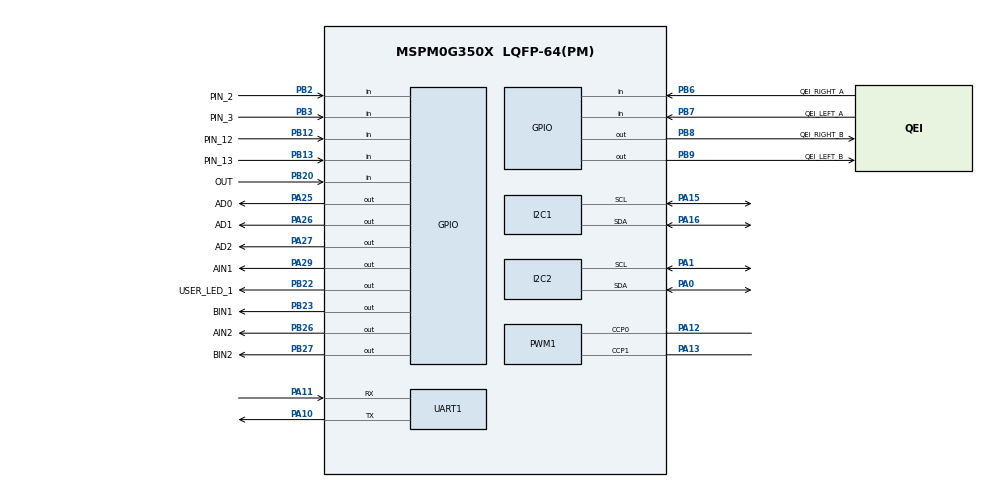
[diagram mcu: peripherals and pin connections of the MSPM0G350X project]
/**
 * @cliArgs --device "MSPM0G350X" --part "Default" --package "LQFP-64(PM)" --product "mspm0_sdk@2.10.00.04"
 * @versions {"tool":"1.26.2+4477"}
 */

/**
 * Import the modules used in this configuration.
 */
const GPIO   = scripting.addModule("/ti/driverlib/GPIO", {}, false);
const GPIO1  = GPIO.addInstance();
const GPIO2  = GPIO.addInstance();
const GPIO3  = GPIO.addInstance();
const GPIO4  = GPIO.addInstance();
const GPIO5  = GPIO.addInstance();
const I2C    = scripting.addModule("/ti/driverlib/I2C", {}, false);
const I2C1   = I2C.addInstance();
const I2C2   = I2C.addInstance();
const PWM    = scripting.addModule("/ti/driverlib/PWM", {}, false);
const PWM1   = PWM.addInstance();
const SYSCTL = scripting.addModule("/ti/driverlib/SYSCTL");
const TIMER  = scripting.addModule("/ti/driverlib/TIMER", {}, false);
const TIMER1 = TIMER.addInstance();
const UART   = scripting.addModule("/ti/driverlib/UART", {}, false);
const UART1  = UART.addInstance();

/**
 * Write custom configuration values to the imported modules.
 */
GPIO1.$name                         = "GPIO_LEDS";
GPIO1.associatedPins[0].$name       = "USER_LED_1";
GPIO1.associatedPins[0].pin.$assign = "PB22";

const Board = scripting.addModule("/ti/driverlib/Board", {}, false);

GPIO2.$name                         = "GPIO_MOTOR";
GPIO2.associatedPins.create(4);
GPIO2.associatedPins[0].$name       = "AIN1";
GPIO2.associatedPins[0].pin.$assign = "PA29";
GPIO2.associatedPins[1].$name       = "AIN2";
GPIO2.associatedPins[1].pin.$assign = "PB26";
GPIO2.associatedPins[2].$name       = "BIN1";
GPIO2.associatedPins[2].pin.$assign = "PB23";
GPIO2.associatedPins[3].$name       = "BIN2";
GPIO2.associatedPins[3].pin.$assign = "PB27";

GPIO3.$name                         = "GPIO_SENSOR";
GPIO3.associatedPins.create(4);
GPIO3.associatedPins[0].$name       = "AD0";
GPIO3.associatedPins[0].pin.$assign = "PA25";
GPIO3.associatedPins[1].$name       = "AD1";
GPIO3.associatedPins[1].pin.$assign = "PA26";
GPIO3.associatedPins[2].$name       = "AD2";
GPIO3.associatedPins[2].pin.$assign = "PA27";
GPIO3.associatedPins[3].$name       = "OUT";
GPIO3.associatedPins[3].direction   = "INPUT";
GPIO3.associatedPins[3].pin.$assign = "PB20";

GPIO4.$name                         = "GPIO_ENCODER";
GPIO4.associatedPins.create(4);
GPIO4.associatedPins[0].$name       = "QEI_LEFT_A";
GPIO4.associatedPins[0].direction   = "INPUT";
GPIO4.associatedPins[0].pin.$assign = "PB7";
GPIO4.associatedPins[1].$name       = "QEI_RIGHT_A";
GPIO4.associatedPins[1].direction   = "INPUT";
GPIO4.associatedPins[1].pin.$assign = "PB6";
GPIO4.associatedPins[2].$name       = "QEI_LEFT_B";
GPIO4.associatedPins[2].pin.$assign = "PB9";
GPIO4.associatedPins[3].$name       = "QEI_RIGHT_B";
GPIO4.associatedPins[3].pin.$assign = "PB8";

GPIO5.$name                              = "GPIO_KEYS";
GPIO5.associatedPins.create(4);
GPIO5.associatedPins[0].$name            = "PIN_2";
GPIO5.associatedPins[0].direction        = "INPUT";
GPIO5.associatedPins[0].internalResistor = "PULL_UP";
GPIO5.associatedPins[0].pin.$assign      = "PB2";
GPIO5.associatedPins[1].$name            = "PIN_3";
GPIO5.associatedPins[1].direction        = "INPUT";
GPIO5.associatedPins[1].internalResistor = "PULL_UP";
GPIO5.associatedPins[1].pin.$assign      = "PB3";
GPIO5.associatedPins[2].$name            = "PIN_12";
GPIO5.associatedPins[2].direction        = "INPUT";
GPIO5.associatedPins[2].internalResistor = "PULL_UP";
GPIO5.associatedPins[2].pin.$assign      = "PB12";
GPIO5.associatedPins[3].$name            = "PIN_13";
GPIO5.associatedPins[3].direction        = "INPUT";
GPIO5.associatedPins[3].internalResistor = "PULL_UP";
GPIO5.associatedPins[3].pin.$assign      = "PB13";

I2C1.$name                     = "I2C_0";
I2C1.peripheral.sdaPin.$assign = "PA16";
I2C1.peripheral.sclPin.$assign = "PA15";
I2C1.sdaPinConfig.$name        = "ti_driverlib_gpio_GPIOPinGeneric0";
I2C1.sclPinConfig.$name        = "ti_driverlib_gpio_GPIOPinGeneric1";

I2C2.$name                     = "I2C_1";
I2C2.peripheral.sdaPin.$assign = "PA0";
I2C2.peripheral.sclPin.$assign = "PA1";
I2C2.sdaPinConfig.$name        = "ti_driverlib_gpio_GPIOPinGeneric6";
I2C2.sclPinConfig.$name        = "ti_driverlib_gpio_GPIOPinGeneric7";

PWM1.$name                              = "PWM_MOTOR";
PWM1.pwmMode                            = "EDGE_ALIGN_UP";
PWM1.timerCount                         = 2000;
PWM1.peripheral.$assign                 = "TIMG0";
PWM1.peripheral.ccp0Pin.$assign         = "PA12";
PWM1.peripheral.ccp1Pin.$assign         = "PA13";
PWM1.PWM_CHANNEL_0.$name                = "ti_driverlib_pwm_PWMTimerCC0";
PWM1.PWM_CHANNEL_1.$name                = "ti_driverlib_pwm_PWMTimerCC1";
PWM1.ccp0PinConfig.$name                = "ti_driverlib_gpio_GPIOPinGeneric2";
PWM1.ccp0PinConfig.direction            = scripting.forceWrite("OUTPUT");
PWM1.ccp0PinConfig.hideOutputInversion  = scripting.forceWrite(false);
PWM1.ccp0PinConfig.onlyInternalResistor = scripting.forceWrite(false);
PWM1.ccp0PinConfig.passedPeripheralType = scripting.forceWrite("Digital");
PWM1.ccp1PinConfig.$name                = "ti_driverlib_gpio_GPIOPinGeneric3";
PWM1.ccp1PinConfig.direction            = scripting.forceWrite("OUTPUT");
PWM1.ccp1PinConfig.hideOutputInversion  = scripting.forceWrite(false);
PWM1.ccp1PinConfig.onlyInternalResistor = scripting.forceWrite(false);
PWM1.ccp1PinConfig.passedPeripheralType = scripting.forceWrite("Digital");

SYSCTL.forceDefaultClkConfig = true;
SYSCTL.clockTreeEn           = true;

TIMER1.$name            = "TIMER_0";
TIMER1.interrupts       = ["ZERO"];
TIMER1.timerMode        = "PERIODIC";
TIMER1.timerPeriod      = "10 ms";
TIMER1.timerClkPrescale = 256;

UART1.$name                            = "UART_BLUETOOTH";
UART1.peripheral.rxPin.$assign         = "PA11";
UART1.peripheral.txPin.$assign         = "PA10";
UART1.txPinConfig.$name                = "ti_driverlib_gpio_GPIOPinGeneric4";
UART1.txPinConfig.direction            = scripting.forceWrite("OUTPUT");
UART1.txPinConfig.hideOutputInversion  = scripting.forceWrite(false);
UART1.txPinConfig.onlyInternalResistor = scripting.forceWrite(false);
UART1.txPinConfig.passedPeripheralType = scripting.forceWrite("Digital");
UART1.rxPinConfig.$name                = "ti_driverlib_gpio_GPIOPinGeneric5";
UART1.rxPinConfig.hideOutputInversion  = scripting.forceWrite(false);
UART1.rxPinConfig.onlyInternalResistor = scripting.forceWrite(false);
UART1.rxPinConfig.passedPeripheralType = scripting.forceWrite("Digital");

/**
 * Pinmux solution for unlocked pins/peripherals. This ensures that minor changes to the automatic solver in a future
 * version of the tool will not impact the pinmux you originally saw.  These lines can be completely deleted in order to
 * re-solve from scratch.
 */
Board.peripheral.$suggestSolution          = "DEBUGSS";
Board.peripheral.swclkPin.$suggestSolution = "PA20";
Board.peripheral.swdioPin.$suggestSolution = "PA19";
I2C1.peripheral.$suggestSolution           = "I2C1";
I2C2.peripheral.$suggestSolution           = "I2C0";
TIMER1.peripheral.$suggestSolution         = "TIMA0";
UART1.peripheral.$suggestSolution          = "UART0";
